# SYSCTRL_PADCONF_CORE register map
Vendor: Texas Instruments
Registers are 32-bit, access per field, reset 0x10F010F unless marked. A register's access mark holds for its fields unless they carry their own. Offsets are as the file gives them; [hi:lo] are bit positions; 'fields as' and 'values as' point back to an identical list.

## SYSCTRL_PADCONF_CORE (part 7 of 10)
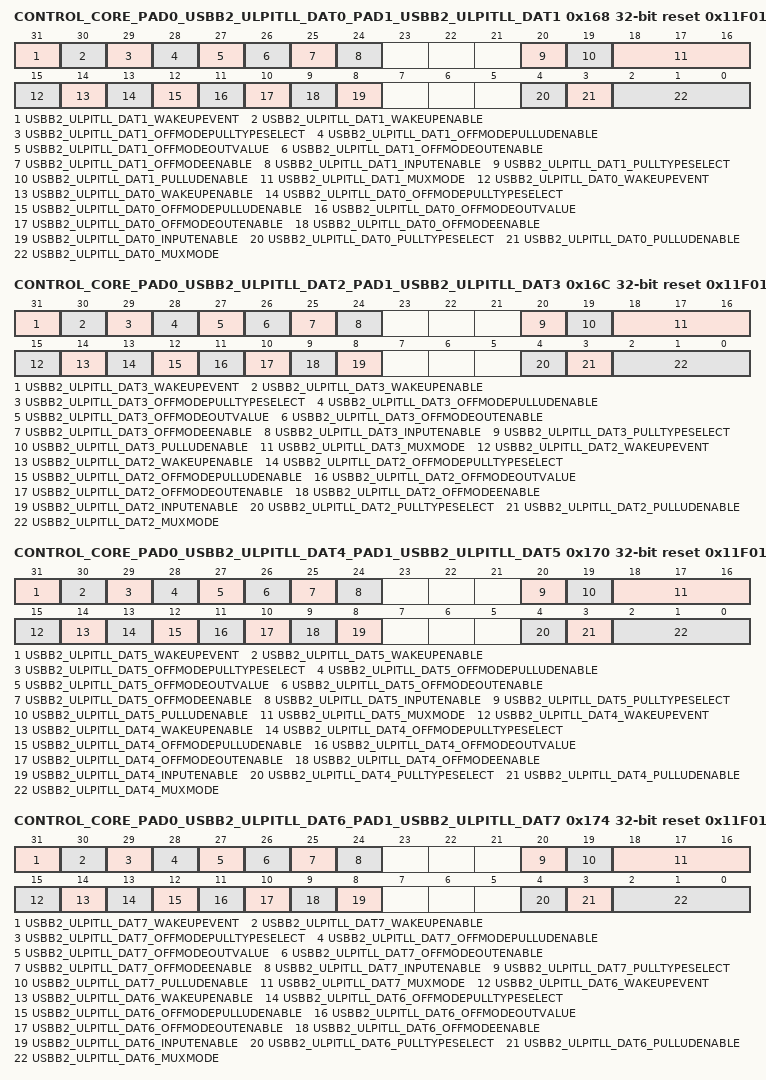
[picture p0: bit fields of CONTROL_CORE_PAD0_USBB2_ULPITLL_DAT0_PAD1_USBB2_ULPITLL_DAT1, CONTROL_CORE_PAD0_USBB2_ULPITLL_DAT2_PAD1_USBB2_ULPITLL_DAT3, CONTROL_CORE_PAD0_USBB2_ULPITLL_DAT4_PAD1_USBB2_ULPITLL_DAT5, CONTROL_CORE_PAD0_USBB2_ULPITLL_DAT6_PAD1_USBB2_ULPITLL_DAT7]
0x168 CONTROL_CORE_PAD0_USBB2_ULPITLL_DAT0_PAD1_USBB2_ULPITLL_DAT1 reset 0x11F011F — Register control for Pads usbb2_ulpitll_dat0 and usbb2_ulpitll_dat1 Access conditions. Read: unrestricted, Write: unrestricted
  [31] USBB2_ULPITLL_DAT1_WAKEUPEVENT ro — Pad_x wake-up event status latched in the IO
    0=USBB2_ULPITLL_DAT1_WAKEUPEVENT_0_r (No wake-up event occurred); 1=USBB2_ULPITLL_DAT1_WAKEUPEVENT_1_r (A wake-up event occurred)
  [30] USBB2_ULPITLL_DAT1_WAKEUPENABLE rw — Input pad wake-up enable (and OFF mode input enable value)
    0=wake-up detection is disabled; 1=wake-up detection is enabled
  [29] USBB2_ULPITLL_DAT1_OFFMODEPULLTYPESELECT rw — OffMode mode pullup/down selection for pad usbb2_ulpitll_dat1
    0=Offmode pulldown selected; 1=Offmode pullup selected
  [28] USBB2_ULPITLL_DAT1_OFFMODEPULLUDENABLE rw — OffMode mode pullup/down enable for pad usbb2_ulpitll_dat1
    0=Offmode pullup/down disabled; 1=Offmode pullup/down enabled
  [27] USBB2_ULPITLL_DAT1_OFFMODEOUTVALUE rw — OffMode mode output value for pad usbb2_ulpitll_dat1
    0=Set value at 0; 1=Set value at 1
  [26] USBB2_ULPITLL_DAT1_OFFMODEOUTENABLE rw — OffMode mode output enable value for pad usbb2_ulpitll_dat1. This is an active low signal
    0=Output enable; 1=Output disable
  [25] USBB2_ULPITLL_DAT1_OFFMODEENABLE rw — OffMode mode override control for pad usbb2_ulpitll_dat1
    0=I/O state keeps its previous state when OFF mode is active; 1=I/O state is forced to OFF mode value when OFF mode is active
  [24] USBB2_ULPITLL_DAT1_INPUTENABLE rw — Input enable value for pad usbb2_ulpitll_dat1
    0=Input buffer of I/O cell is disabled; 1=Input buffer of I/O cell is enabled
  [20] USBB2_ULPITLL_DAT1_PULLTYPESELECT rw — pullup/down selection for pad usbb2_ulpitll_dat1
    0=pulldown selected; 1=pullup selected
  [19] USBB2_ULPITLL_DAT1_PULLUDENABLE rw — pullup/down enable for pad usbb2_ulpitll_dat1
    0=pullup/down disabled; 1=pullup/down enabled
  [18:16] USBB2_ULPITLL_DAT1_MUXMODE rw — Functional multiplexing selection for pad usbb2_ulpitll_dat1
    0=Select usbb2_ulpitll_dat1; 1=Select usbb2_ulpiphy_dat1; 2=Select sdmmc4_dat3; 3=Select gpio_162; 4=Select hsi2_acdata; 5=Select dispc2_data19; 6=Select usbb2_mm_txdat; 7=Select safe_mode
  [15] USBB2_ULPITLL_DAT0_WAKEUPEVENT ro — Pad_x wake-up event status latched in the IO
    0=USBB2_ULPITLL_DAT0_WAKEUPEVENT_0_r (No wake-up event occurred); 1=USBB2_ULPITLL_DAT0_WAKEUPEVENT_1_r (A wake-up event occurred)
  [14] USBB2_ULPITLL_DAT0_WAKEUPENABLE rw — Input pad wake-up enable (and OFF mode input enable value)
    values as USBB2_ULPITLL_DAT1_WAKEUPENABLE
  [13] USBB2_ULPITLL_DAT0_OFFMODEPULLTYPESELECT rw — OffMode mode pullup/down selection for pad usbb2_ulpitll_dat0
    0=Offmode pulldown selected; 1=Offmode pullup selected
  [12] USBB2_ULPITLL_DAT0_OFFMODEPULLUDENABLE rw — OffMode mode pullup/down enable for pad usbb2_ulpitll_dat0
    values as USBB2_ULPITLL_DAT1_OFFMODEPULLUDENABLE
  [11] USBB2_ULPITLL_DAT0_OFFMODEOUTVALUE rw — OffMode mode output value for pad usbb2_ulpitll_dat0
    0=Set value at 0; 1=Set value at 1
  [10] USBB2_ULPITLL_DAT0_OFFMODEOUTENABLE rw — OffMode mode output enable value for pad usbb2_ulpitll_dat0. This is an active low signal
    0=Output enable; 1=Output disable
  [9] USBB2_ULPITLL_DAT0_OFFMODEENABLE rw — OffMode mode override control for pad usbb2_ulpitll_dat0
    values as USBB2_ULPITLL_DAT1_OFFMODEENABLE
  [8] USBB2_ULPITLL_DAT0_INPUTENABLE rw — Input enable value for pad usbb2_ulpitll_dat0
    values as USBB2_ULPITLL_DAT1_INPUTENABLE
  [4] USBB2_ULPITLL_DAT0_PULLTYPESELECT rw — pullup/down selection for pad usbb2_ulpitll_dat0
    0=pulldown selected; 1=pullup selected
  [3] USBB2_ULPITLL_DAT0_PULLUDENABLE rw — pullup/down enable for pad usbb2_ulpitll_dat0
    0=pullup/down disabled; 1=pullup/down enabled
  [2:0] USBB2_ULPITLL_DAT0_MUXMODE rw — Functional multiplexing selection for pad usbb2_ulpitll_dat0
    0=Select usbb2_ulpitll_dat0; 1=Select usbb2_ulpiphy_dat0; 2=Select sdmmc4_dat2; 3=Select gpio_161; 4=Select hsi2_acwake; 5=Select dispc2_data20; 6=Select usbb2_mm_txen; 7=Select safe_mode
0x16C CONTROL_CORE_PAD0_USBB2_ULPITLL_DAT2_PAD1_USBB2_ULPITLL_DAT3 reset 0x11F010F — Register control for Pads usbb2_ulpitll_dat2 and usbb2_ulpitll_dat3 Access conditions. Read: unrestricted, Write: unrestricted
  [31] USBB2_ULPITLL_DAT3_WAKEUPEVENT ro — Pad_x wake-up event status latched in the IO
    0=USBB2_ULPITLL_DAT3_WAKEUPEVENT_0_r (No wake-up event occurred); 1=USBB2_ULPITLL_DAT3_WAKEUPEVENT_1_r (A wake-up event occurred)
  [30] USBB2_ULPITLL_DAT3_WAKEUPENABLE rw — Input pad wake-up enable (and OFF mode input enable value)
    values as CONTROL_CORE_PAD0_USBB2_ULPITLL_DAT0_PAD1_USBB2_ULPITLL_DAT1.USBB2_ULPITLL_DAT1_WAKEUPENABLE
  [29] USBB2_ULPITLL_DAT3_OFFMODEPULLTYPESELECT rw — OffMode mode pullup/down selection for pad usbb2_ulpitll_dat3
    0=Offmode pulldown selected; 1=Offmode pullup selected
  [28] USBB2_ULPITLL_DAT3_OFFMODEPULLUDENABLE rw — OffMode mode pullup/down enable for pad usbb2_ulpitll_dat3
    values as CONTROL_CORE_PAD0_USBB2_ULPITLL_DAT0_PAD1_USBB2_ULPITLL_DAT1.USBB2_ULPITLL_DAT1_OFFMODEPULLUDENABLE
  [27] USBB2_ULPITLL_DAT3_OFFMODEOUTVALUE rw — OffMode mode output value for pad usbb2_ulpitll_dat3
    0=Set value at 0; 1=Set value at 1
  [26] USBB2_ULPITLL_DAT3_OFFMODEOUTENABLE rw — OffMode mode output enable value for pad usbb2_ulpitll_dat3. This is an active low signal
    0=Output enable; 1=Output disable
  [25] USBB2_ULPITLL_DAT3_OFFMODEENABLE rw — OffMode mode override control for pad usbb2_ulpitll_dat3
    values as CONTROL_CORE_PAD0_USBB2_ULPITLL_DAT0_PAD1_USBB2_ULPITLL_DAT1.USBB2_ULPITLL_DAT1_OFFMODEENABLE
  [24] USBB2_ULPITLL_DAT3_INPUTENABLE rw — Input enable value for pad usbb2_ulpitll_dat3
    values as CONTROL_CORE_PAD0_USBB2_ULPITLL_DAT0_PAD1_USBB2_ULPITLL_DAT1.USBB2_ULPITLL_DAT1_INPUTENABLE
  [20] USBB2_ULPITLL_DAT3_PULLTYPESELECT rw — pullup/down selection for pad usbb2_ulpitll_dat3
    0=pulldown selected; 1=pullup selected
  [19] USBB2_ULPITLL_DAT3_PULLUDENABLE rw — pullup/down enable for pad usbb2_ulpitll_dat3
    0=pullup/down disabled; 1=pullup/down enabled
  [18:16] USBB2_ULPITLL_DAT3_MUXMODE rw — Functional multiplexing selection for pad usbb2_ulpitll_dat3
    0=Select usbb2_ulpitll_dat3; 1=Select usbb2_ulpiphy_dat3; 2=Select sdmmc3_dat1; 3=Select gpio_164; 4=Select hsi2_caready; 5=Select dispc2_data15; 6=Select rfbi_data15; 7=Select safe_mode
  [15] USBB2_ULPITLL_DAT2_WAKEUPEVENT ro — Pad_x wake-up event status latched in the IO
    0=USBB2_ULPITLL_DAT2_WAKEUPEVENT_0_r (No wake-up event occurred); 1=USBB2_ULPITLL_DAT2_WAKEUPEVENT_1_r (A wake-up event occurred)
  [14] USBB2_ULPITLL_DAT2_WAKEUPENABLE rw — Input pad wake-up enable (and OFF mode input enable value)
    values as CONTROL_CORE_PAD0_USBB2_ULPITLL_DAT0_PAD1_USBB2_ULPITLL_DAT1.USBB2_ULPITLL_DAT1_WAKEUPENABLE
  [13] USBB2_ULPITLL_DAT2_OFFMODEPULLTYPESELECT rw — OffMode mode pullup/down selection for pad usbb2_ulpitll_dat2
    0=Offmode pulldown selected; 1=Offmode pullup selected
  [12] USBB2_ULPITLL_DAT2_OFFMODEPULLUDENABLE rw — OffMode mode pullup/down enable for pad usbb2_ulpitll_dat2
    values as CONTROL_CORE_PAD0_USBB2_ULPITLL_DAT0_PAD1_USBB2_ULPITLL_DAT1.USBB2_ULPITLL_DAT1_OFFMODEPULLUDENABLE
  [11] USBB2_ULPITLL_DAT2_OFFMODEOUTVALUE rw — OffMode mode output value for pad usbb2_ulpitll_dat2
    0=Set value at 0; 1=Set value at 1
  [10] USBB2_ULPITLL_DAT2_OFFMODEOUTENABLE rw — OffMode mode output enable value for pad usbb2_ulpitll_dat2. This is an active low signal
    0=Output enable; 1=Output disable
  [9] USBB2_ULPITLL_DAT2_OFFMODEENABLE rw — OffMode mode override control for pad usbb2_ulpitll_dat2
    values as CONTROL_CORE_PAD0_USBB2_ULPITLL_DAT0_PAD1_USBB2_ULPITLL_DAT1.USBB2_ULPITLL_DAT1_OFFMODEENABLE
  [8] USBB2_ULPITLL_DAT2_INPUTENABLE rw — Input enable value for pad usbb2_ulpitll_dat2
    values as CONTROL_CORE_PAD0_USBB2_ULPITLL_DAT0_PAD1_USBB2_ULPITLL_DAT1.USBB2_ULPITLL_DAT1_INPUTENABLE
  [4] USBB2_ULPITLL_DAT2_PULLTYPESELECT rw — pullup/down selection for pad usbb2_ulpitll_dat2
    0=pulldown selected; 1=pullup selected
  [3] USBB2_ULPITLL_DAT2_PULLUDENABLE rw — pullup/down enable for pad usbb2_ulpitll_dat2
    0=pullup/down disabled; 1=pullup/down enabled
  [2:0] USBB2_ULPITLL_DAT2_MUXMODE rw — Functional multiplexing selection for pad usbb2_ulpitll_dat2
    0=Select usbb2_ulpitll_dat2; 1=Select usbb2_ulpiphy_dat2; 2=Select sdmmc3_dat2; 3=Select gpio_163; 4=Select hsi2_acflag; 5=Select dispc2_data18; 6=Select usbb2_mm_txse0; 7=Select safe_mode
0x170 CONTROL_CORE_PAD0_USBB2_ULPITLL_DAT4_PAD1_USBB2_ULPITLL_DAT5 reset 0x11F011F — Register control for Pads usbb2_ulpitll_dat4 and usbb2_ulpitll_dat5 Access conditions. Read: unrestricted, Write: unrestricted
  [31] USBB2_ULPITLL_DAT5_WAKEUPEVENT ro — Pad_x wake-up event status latched in the IO
    0=USBB2_ULPITLL_DAT5_WAKEUPEVENT_0_r (No wake-up event occurred); 1=USBB2_ULPITLL_DAT5_WAKEUPEVENT_1_r (A wake-up event occurred)
  [30] USBB2_ULPITLL_DAT5_WAKEUPENABLE rw — Input pad wake-up enable (and OFF mode input enable value)
    values as CONTROL_CORE_PAD0_USBB2_ULPITLL_DAT0_PAD1_USBB2_ULPITLL_DAT1.USBB2_ULPITLL_DAT1_WAKEUPENABLE
  [29] USBB2_ULPITLL_DAT5_OFFMODEPULLTYPESELECT rw — OffMode mode pullup/down selection for pad usbb2_ulpitll_dat5
    0=Offmode pulldown selected; 1=Offmode pullup selected
  [28] USBB2_ULPITLL_DAT5_OFFMODEPULLUDENABLE rw — OffMode mode pullup/down enable for pad usbb2_ulpitll_dat5
    values as CONTROL_CORE_PAD0_USBB2_ULPITLL_DAT0_PAD1_USBB2_ULPITLL_DAT1.USBB2_ULPITLL_DAT1_OFFMODEPULLUDENABLE
  [27] USBB2_ULPITLL_DAT5_OFFMODEOUTVALUE rw — OffMode mode output value for pad usbb2_ulpitll_dat5
    0=Set value at 0; 1=Set value at 1
  [26] USBB2_ULPITLL_DAT5_OFFMODEOUTENABLE rw — OffMode mode output enable value for pad usbb2_ulpitll_dat5. This is an active low signal
    0=Output enable; 1=Output disable
  [25] USBB2_ULPITLL_DAT5_OFFMODEENABLE rw — OffMode mode override control for pad usbb2_ulpitll_dat5
    values as CONTROL_CORE_PAD0_USBB2_ULPITLL_DAT0_PAD1_USBB2_ULPITLL_DAT1.USBB2_ULPITLL_DAT1_OFFMODEENABLE
  [24] USBB2_ULPITLL_DAT5_INPUTENABLE rw — Input enable value for pad usbb2_ulpitll_dat5
    values as CONTROL_CORE_PAD0_USBB2_ULPITLL_DAT0_PAD1_USBB2_ULPITLL_DAT1.USBB2_ULPITLL_DAT1_INPUTENABLE
  [20] USBB2_ULPITLL_DAT5_PULLTYPESELECT rw — pullup/down selection for pad usbb2_ulpitll_dat5
    0=pulldown selected; 1=pullup selected
  [19] USBB2_ULPITLL_DAT5_PULLUDENABLE rw — pullup/down enable for pad usbb2_ulpitll_dat5
    0=pullup/down disabled; 1=pullup/down enabled
  [18:16] USBB2_ULPITLL_DAT5_MUXMODE rw — Functional multiplexing selection for pad usbb2_ulpitll_dat5
    0=Select usbb2_ulpitll_dat5; 1=Select usbb2_ulpiphy_dat5; 2=Select sdmmc3_dat3; 3=Select gpio_166; 4=Select mcspi3_cs0; 5=Select dispc2_data13; 6=Select rfbi_data13; 7=Select safe_mode
  [15] USBB2_ULPITLL_DAT4_WAKEUPEVENT ro — Pad_x wake-up event status latched in the IO
    0=USBB2_ULPITLL_DAT4_WAKEUPEVENT_0_r (No wake-up event occurred); 1=USBB2_ULPITLL_DAT4_WAKEUPEVENT_1_r (A wake-up event occurred)
  [14] USBB2_ULPITLL_DAT4_WAKEUPENABLE rw — Input pad wake-up enable (and OFF mode input enable value)
    values as CONTROL_CORE_PAD0_USBB2_ULPITLL_DAT0_PAD1_USBB2_ULPITLL_DAT1.USBB2_ULPITLL_DAT1_WAKEUPENABLE
  [13] USBB2_ULPITLL_DAT4_OFFMODEPULLTYPESELECT rw — OffMode mode pullup/down selection for pad usbb2_ulpitll_dat4
    0=Offmode pulldown selected; 1=Offmode pullup selected
  [12] USBB2_ULPITLL_DAT4_OFFMODEPULLUDENABLE rw — OffMode mode pullup/down enable for pad usbb2_ulpitll_dat4
    values as CONTROL_CORE_PAD0_USBB2_ULPITLL_DAT0_PAD1_USBB2_ULPITLL_DAT1.USBB2_ULPITLL_DAT1_OFFMODEPULLUDENABLE
  [11] USBB2_ULPITLL_DAT4_OFFMODEOUTVALUE rw — OffMode mode output value for pad usbb2_ulpitll_dat4
    0=Set value at 0; 1=Set value at 1
  [10] USBB2_ULPITLL_DAT4_OFFMODEOUTENABLE rw — OffMode mode output enable value for pad usbb2_ulpitll_dat4. This is an active low signal
    0=Output enable; 1=Output disable
  [9] USBB2_ULPITLL_DAT4_OFFMODEENABLE rw — OffMode mode override control for pad usbb2_ulpitll_dat4
    values as CONTROL_CORE_PAD0_USBB2_ULPITLL_DAT0_PAD1_USBB2_ULPITLL_DAT1.USBB2_ULPITLL_DAT1_OFFMODEENABLE
  [8] USBB2_ULPITLL_DAT4_INPUTENABLE rw — Input enable value for pad usbb2_ulpitll_dat4
    values as CONTROL_CORE_PAD0_USBB2_ULPITLL_DAT0_PAD1_USBB2_ULPITLL_DAT1.USBB2_ULPITLL_DAT1_INPUTENABLE
  [4] USBB2_ULPITLL_DAT4_PULLTYPESELECT rw — pullup/down selection for pad usbb2_ulpitll_dat4
    0=pulldown selected; 1=pullup selected
  [3] USBB2_ULPITLL_DAT4_PULLUDENABLE rw — pullup/down enable for pad usbb2_ulpitll_dat4
    0=pullup/down disabled; 1=pullup/down enabled
  [2:0] USBB2_ULPITLL_DAT4_MUXMODE rw — Functional multiplexing selection for pad usbb2_ulpitll_dat4
    0=Select usbb2_ulpitll_dat4; 1=Select usbb2_ulpiphy_dat4; 2=Select sdmmc3_dat0; 3=Select gpio_165; 4=Select mcspi3_somi; 5=Select dispc2_data14; 6=Select rfbi_data14; 7=Select safe_mode
0x174 CONTROL_CORE_PAD0_USBB2_ULPITLL_DAT6_PAD1_USBB2_ULPITLL_DAT7 reset 0x11F011F — Register control for Pads usbb2_ulpitll_dat6 and usbb2_ulpitll_dat7 Access conditions. Read: unrestricted, Write: unrestricted
  [31] USBB2_ULPITLL_DAT7_WAKEUPEVENT ro — Pad_x wake-up event status latched in the IO
    0=USBB2_ULPITLL_DAT7_WAKEUPEVENT_0_r (No wake-up event occurred); 1=USBB2_ULPITLL_DAT7_WAKEUPEVENT_1_r (A wake-up event occurred)
  [30] USBB2_ULPITLL_DAT7_WAKEUPENABLE rw — Input pad wake-up enable (and OFF mode input enable value)
    values as CONTROL_CORE_PAD0_USBB2_ULPITLL_DAT0_PAD1_USBB2_ULPITLL_DAT1.USBB2_ULPITLL_DAT1_WAKEUPENABLE
  [29] USBB2_ULPITLL_DAT7_OFFMODEPULLTYPESELECT rw — OffMode mode pullup/down selection for pad usbb2_ulpitll_dat7
    0=Offmode pulldown selected; 1=Offmode pullup selected
  [28] USBB2_ULPITLL_DAT7_OFFMODEPULLUDENABLE rw — OffMode mode pullup/down enable for pad usbb2_ulpitll_dat7
    values as CONTROL_CORE_PAD0_USBB2_ULPITLL_DAT0_PAD1_USBB2_ULPITLL_DAT1.USBB2_ULPITLL_DAT1_OFFMODEPULLUDENABLE
  [27] USBB2_ULPITLL_DAT7_OFFMODEOUTVALUE rw — OffMode mode output value for pad usbb2_ulpitll_dat7
    0=Set value at 0; 1=Set value at 1
  [26] USBB2_ULPITLL_DAT7_OFFMODEOUTENABLE rw — OffMode mode output enable value for pad usbb2_ulpitll_dat7. This is an active low signal
    0=Output enable; 1=Output disable
  [25] USBB2_ULPITLL_DAT7_OFFMODEENABLE rw — OffMode mode override control for pad usbb2_ulpitll_dat7
    values as CONTROL_CORE_PAD0_USBB2_ULPITLL_DAT0_PAD1_USBB2_ULPITLL_DAT1.USBB2_ULPITLL_DAT1_OFFMODEENABLE
  [24] USBB2_ULPITLL_DAT7_INPUTENABLE rw — Input enable value for pad usbb2_ulpitll_dat7
    values as CONTROL_CORE_PAD0_USBB2_ULPITLL_DAT0_PAD1_USBB2_ULPITLL_DAT1.USBB2_ULPITLL_DAT1_INPUTENABLE
  [20] USBB2_ULPITLL_DAT7_PULLTYPESELECT rw — pullup/down selection for pad usbb2_ulpitll_dat7
    0=pulldown selected; 1=pullup selected
  [19] USBB2_ULPITLL_DAT7_PULLUDENABLE rw — pullup/down enable for pad usbb2_ulpitll_dat7
    0=pullup/down disabled; 1=pullup/down enabled
  [18:16] USBB2_ULPITLL_DAT7_MUXMODE rw — Functional multiplexing selection for pad usbb2_ulpitll_dat7
    0=Select usbb2_ulpitll_dat7; 1=Select usbb2_ulpiphy_dat7; 2=Select sdmmc3_clk; 3=Select gpio_168; 4=Select mcspi3_clk; 5=Select dispc2_data11; 6=Select rfbi_data11; 7=Select safe_mode
  [15] USBB2_ULPITLL_DAT6_WAKEUPEVENT ro — Pad_x wake-up event status latched in the IO
    0=USBB2_ULPITLL_DAT6_WAKEUPEVENT_0_r (No wake-up event occurred); 1=USBB2_ULPITLL_DAT6_WAKEUPEVENT_1_r (A wake-up event occurred)
  [14] USBB2_ULPITLL_DAT6_WAKEUPENABLE rw — Input pad wake-up enable (and OFF mode input enable value)
    values as CONTROL_CORE_PAD0_USBB2_ULPITLL_DAT0_PAD1_USBB2_ULPITLL_DAT1.USBB2_ULPITLL_DAT1_WAKEUPENABLE
  [13] USBB2_ULPITLL_DAT6_OFFMODEPULLTYPESELECT rw — OffMode mode pullup/down selection for pad usbb2_ulpitll_dat6
    0=Offmode pulldown selected; 1=Offmode pullup selected
  [12] USBB2_ULPITLL_DAT6_OFFMODEPULLUDENABLE rw — OffMode mode pullup/down enable for pad usbb2_ulpitll_dat6
    values as CONTROL_CORE_PAD0_USBB2_ULPITLL_DAT0_PAD1_USBB2_ULPITLL_DAT1.USBB2_ULPITLL_DAT1_OFFMODEPULLUDENABLE
  [11] USBB2_ULPITLL_DAT6_OFFMODEOUTVALUE rw — OffMode mode output value for pad usbb2_ulpitll_dat6
    0=Set value at 0; 1=Set value at 1
  [10] USBB2_ULPITLL_DAT6_OFFMODEOUTENABLE rw — OffMode mode output enable value for pad usbb2_ulpitll_dat6. This is an active low signal
    0=Output enable; 1=Output disable
  [9] USBB2_ULPITLL_DAT6_OFFMODEENABLE rw — OffMode mode override control for pad usbb2_ulpitll_dat6
    values as CONTROL_CORE_PAD0_USBB2_ULPITLL_DAT0_PAD1_USBB2_ULPITLL_DAT1.USBB2_ULPITLL_DAT1_OFFMODEENABLE
  [8] USBB2_ULPITLL_DAT6_INPUTENABLE rw — Input enable value for pad usbb2_ulpitll_dat6
    values as CONTROL_CORE_PAD0_USBB2_ULPITLL_DAT0_PAD1_USBB2_ULPITLL_DAT1.USBB2_ULPITLL_DAT1_INPUTENABLE
  [4] USBB2_ULPITLL_DAT6_PULLTYPESELECT rw — pullup/down selection for pad usbb2_ulpitll_dat6
    0=pulldown selected; 1=pullup selected
  [3] USBB2_ULPITLL_DAT6_PULLUDENABLE rw — pullup/down enable for pad usbb2_ulpitll_dat6
    0=pullup/down disabled; 1=pullup/down enabled
  [2:0] USBB2_ULPITLL_DAT6_MUXMODE rw — Functional multiplexing selection for pad usbb2_ulpitll_dat6
    0=Select usbb2_ulpitll_dat6; 1=Select usbb2_ulpiphy_dat6; 2=Select sdmmc3_cmd; 3=Select gpio_167; 4=Select mcspi3_simo; 5=Select dispc2_data12; 6=Select rfbi_data12; 7=Select safe_mode
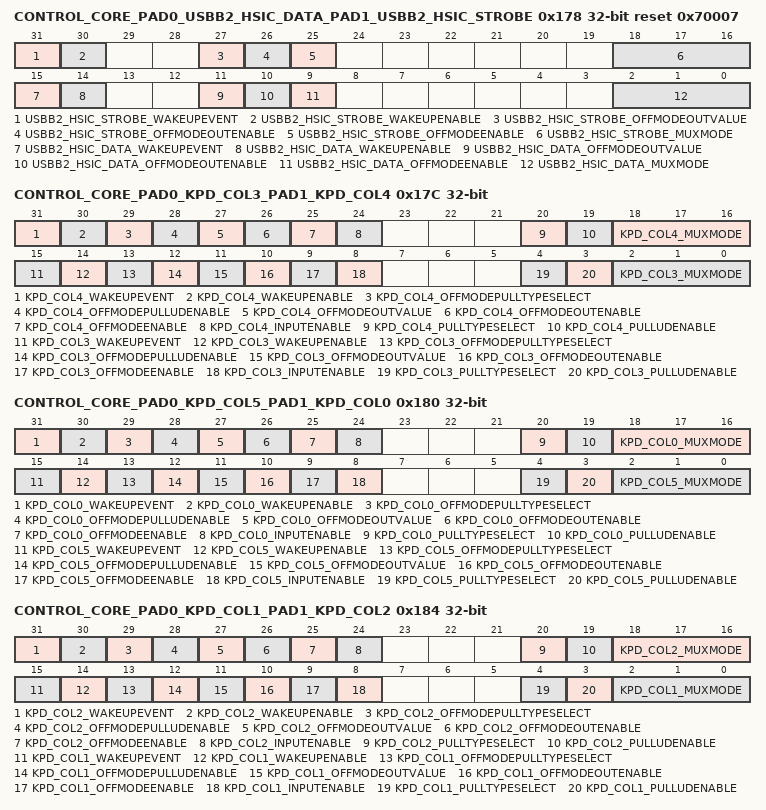
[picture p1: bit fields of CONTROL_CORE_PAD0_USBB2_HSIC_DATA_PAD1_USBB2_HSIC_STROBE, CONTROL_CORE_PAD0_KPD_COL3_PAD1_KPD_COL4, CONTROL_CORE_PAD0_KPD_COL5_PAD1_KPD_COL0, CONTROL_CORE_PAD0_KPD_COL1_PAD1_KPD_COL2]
0x178 CONTROL_CORE_PAD0_USBB2_HSIC_DATA_PAD1_USBB2_HSIC_STROBE reset 0x70007 — Register control for Pads usbb2_hsic_data and usbb2_hsic_strobe Access conditions. Read: unrestricted, Write: unrestricted
  [31] USBB2_HSIC_STROBE_WAKEUPEVENT ro — Pad_x wake-up event status latched in the IO
    0=USBB2_HSIC_STROBE_WAKEUPEVENT_0_r (No wake-up event occurred); 1=USBB2_HSIC_STROBE_WAKEUPEVENT_1_r (A wake-up event occurred)
  [30] USBB2_HSIC_STROBE_WAKEUPENABLE rw — Input pad wake-up enable (and OFF mode input enable value)
    values as CONTROL_CORE_PAD0_USBB2_ULPITLL_DAT0_PAD1_USBB2_ULPITLL_DAT1.USBB2_ULPITLL_DAT1_WAKEUPENABLE
  [27] USBB2_HSIC_STROBE_OFFMODEOUTVALUE rw — OffMode mode output value for pad usbb2_hsic_strobe
    0=Set value at 0; 1=Set value at 1
  [26] USBB2_HSIC_STROBE_OFFMODEOUTENABLE rw — OffMode mode output enable value for pad usbb2_hsic_strobe. This is an active low signal
    0=Output enable; 1=Output disable
  [25] USBB2_HSIC_STROBE_OFFMODEENABLE rw — OffMode mode override control for pad usbb2_hsic_strobe
    values as CONTROL_CORE_PAD0_USBB2_ULPITLL_DAT0_PAD1_USBB2_ULPITLL_DAT1.USBB2_ULPITLL_DAT1_OFFMODEENABLE
  [18:16] USBB2_HSIC_STROBE_MUXMODE rw — Functional multiplexing selection for pad usbb2_hsic_strobe
    0=Select usbb2_hsic_strobe; 3=Select gpio_170; 7=Select safe_mode
  [15] USBB2_HSIC_DATA_WAKEUPEVENT ro — Pad_x wake-up event status latched in the IO
    0=USBB2_HSIC_DATA_WAKEUPEVENT_0_r (No wake-up event occurred); 1=USBB2_HSIC_DATA_WAKEUPEVENT_1_r (A wake-up event occurred)
  [14] USBB2_HSIC_DATA_WAKEUPENABLE rw — Input pad wake-up enable (and OFF mode input enable value)
    values as CONTROL_CORE_PAD0_USBB2_ULPITLL_DAT0_PAD1_USBB2_ULPITLL_DAT1.USBB2_ULPITLL_DAT1_WAKEUPENABLE
  [11] USBB2_HSIC_DATA_OFFMODEOUTVALUE rw — OffMode mode output value for pad usbb2_hsic_data
    0=Set value at 0; 1=Set value at 1
  [10] USBB2_HSIC_DATA_OFFMODEOUTENABLE rw — OffMode mode output enable value for pad usbb2_hsic_data. This is an active low signal
    0=Output enable; 1=Output disable
  [9] USBB2_HSIC_DATA_OFFMODEENABLE rw — OffMode mode override control for pad usbb2_hsic_data
    values as CONTROL_CORE_PAD0_USBB2_ULPITLL_DAT0_PAD1_USBB2_ULPITLL_DAT1.USBB2_ULPITLL_DAT1_OFFMODEENABLE
  [2:0] USBB2_HSIC_DATA_MUXMODE rw — Functional multiplexing selection for pad usbb2_hsic_data
    0=Select usbb2_hsic_data; 3=Select gpio_169; 7=Select safe_mode
0x17C CONTROL_CORE_PAD0_KPD_COL3_PAD1_KPD_COL4 — Register control for Pads kpd_col3 and kpd_col4 Access conditions. Read: unrestricted, Write: unrestricted
  [31] KPD_COL4_WAKEUPEVENT ro — Pad_x wake-up event status latched in the IO
    0=KPD_COL4_WAKEUPEVENT_0_r (No wake-up event occurred); 1=KPD_COL4_WAKEUPEVENT_1_r (A wake-up event occurred)
  [30] KPD_COL4_WAKEUPENABLE rw — Input pad wake-up enable (and OFF mode input enable value)
    values as CONTROL_CORE_PAD0_USBB2_ULPITLL_DAT0_PAD1_USBB2_ULPITLL_DAT1.USBB2_ULPITLL_DAT1_WAKEUPENABLE
  [29] KPD_COL4_OFFMODEPULLTYPESELECT rw — OffMode mode pullup/down selection for pad kpd_col4
    0=Offmode pulldown selected; 1=Offmode pullup selected
  [28] KPD_COL4_OFFMODEPULLUDENABLE rw — OffMode mode pullup/down enable for pad kpd_col4
    values as CONTROL_CORE_PAD0_USBB2_ULPITLL_DAT0_PAD1_USBB2_ULPITLL_DAT1.USBB2_ULPITLL_DAT1_OFFMODEPULLUDENABLE
  [27] KPD_COL4_OFFMODEOUTVALUE rw — OffMode mode output value for pad kpd_col4
    0=Set value at 0; 1=Set value at 1
  [26] KPD_COL4_OFFMODEOUTENABLE rw — OffMode mode output enable value for pad kpd_col4. This is an active low signal
    0=Output enable; 1=Output disable
  [25] KPD_COL4_OFFMODEENABLE rw — OffMode mode override control for pad kpd_col4
    values as CONTROL_CORE_PAD0_USBB2_ULPITLL_DAT0_PAD1_USBB2_ULPITLL_DAT1.USBB2_ULPITLL_DAT1_OFFMODEENABLE
  [24] KPD_COL4_INPUTENABLE rw — Input enable value for pad kpd_col4
    values as CONTROL_CORE_PAD0_USBB2_ULPITLL_DAT0_PAD1_USBB2_ULPITLL_DAT1.USBB2_ULPITLL_DAT1_INPUTENABLE
  [20] KPD_COL4_PULLTYPESELECT rw — pullup/down selection for pad kpd_col4
    0=pulldown selected; 1=pullup selected
  [19] KPD_COL4_PULLUDENABLE rw — pullup/down enable for pad kpd_col4
    0=pullup/down disabled; 1=pullup/down enabled
  [18:16] KPD_COL4_MUXMODE rw — Functional multiplexing selection for pad kpd_col4
    0=Select kpd_col4; 1=Select kpd_col1; 3=Select gpio_172; 7=Select safe_mode
  [15] KPD_COL3_WAKEUPEVENT ro — Pad_x wake-up event status latched in the IO
    0=KPD_COL3_WAKEUPEVENT_0_r (No wake-up event occurred); 1=KPD_COL3_WAKEUPEVENT_1_r (A wake-up event occurred)
  [14] KPD_COL3_WAKEUPENABLE rw — Input pad wake-up enable (and OFF mode input enable value)
    values as CONTROL_CORE_PAD0_USBB2_ULPITLL_DAT0_PAD1_USBB2_ULPITLL_DAT1.USBB2_ULPITLL_DAT1_WAKEUPENABLE
  [13] KPD_COL3_OFFMODEPULLTYPESELECT rw — OffMode mode pullup/down selection for pad kpd_col3
    0=Offmode pulldown selected; 1=Offmode pullup selected
  [12] KPD_COL3_OFFMODEPULLUDENABLE rw — OffMode mode pullup/down enable for pad kpd_col3
    values as CONTROL_CORE_PAD0_USBB2_ULPITLL_DAT0_PAD1_USBB2_ULPITLL_DAT1.USBB2_ULPITLL_DAT1_OFFMODEPULLUDENABLE
  [11] KPD_COL3_OFFMODEOUTVALUE rw — OffMode mode output value for pad kpd_col3
    0=Set value at 0; 1=Set value at 1
  [10] KPD_COL3_OFFMODEOUTENABLE rw — OffMode mode output enable value for pad kpd_col3. This is an active low signal
    0=Output enable; 1=Output disable
  [9] KPD_COL3_OFFMODEENABLE rw — OffMode mode override control for pad kpd_col3
    values as CONTROL_CORE_PAD0_USBB2_ULPITLL_DAT0_PAD1_USBB2_ULPITLL_DAT1.USBB2_ULPITLL_DAT1_OFFMODEENABLE
  [8] KPD_COL3_INPUTENABLE rw — Input enable value for pad kpd_col3
    values as CONTROL_CORE_PAD0_USBB2_ULPITLL_DAT0_PAD1_USBB2_ULPITLL_DAT1.USBB2_ULPITLL_DAT1_INPUTENABLE
  [4] KPD_COL3_PULLTYPESELECT rw — pullup/down selection for pad kpd_col3
    0=pulldown selected; 1=pullup selected
  [3] KPD_COL3_PULLUDENABLE rw — pullup/down enable for pad kpd_col3
    0=pullup/down disabled; 1=pullup/down enabled
  [2:0] KPD_COL3_MUXMODE rw — Functional multiplexing selection for pad kpd_col3
    0=Select kpd_col3; 1=Select kpd_col0; 3=Select gpio_171; 7=Select safe_mode
0x180 CONTROL_CORE_PAD0_KPD_COL5_PAD1_KPD_COL0 — Register control for Pads kpd_col5 and kpd_col0 Access conditions. Read: unrestricted, Write: unrestricted
  [31] KPD_COL0_WAKEUPEVENT ro — Pad_x wake-up event status latched in the IO
    0=KPD_COL0_WAKEUPEVENT_0_r (No wake-up event occurred); 1=KPD_COL0_WAKEUPEVENT_1_r (A wake-up event occurred)
  [30] KPD_COL0_WAKEUPENABLE rw — Input pad wake-up enable (and OFF mode input enable value)
    values as CONTROL_CORE_PAD0_USBB2_ULPITLL_DAT0_PAD1_USBB2_ULPITLL_DAT1.USBB2_ULPITLL_DAT1_WAKEUPENABLE
  [29] KPD_COL0_OFFMODEPULLTYPESELECT rw — OffMode mode pullup/down selection for pad kpd_col0
    0=Offmode pulldown selected; 1=Offmode pullup selected
  [28] KPD_COL0_OFFMODEPULLUDENABLE rw — OffMode mode pullup/down enable for pad kpd_col0
    values as CONTROL_CORE_PAD0_USBB2_ULPITLL_DAT0_PAD1_USBB2_ULPITLL_DAT1.USBB2_ULPITLL_DAT1_OFFMODEPULLUDENABLE
  [27] KPD_COL0_OFFMODEOUTVALUE rw — OffMode mode output value for pad kpd_col0
    0=Set value at 0; 1=Set value at 1
  [26] KPD_COL0_OFFMODEOUTENABLE rw — OffMode mode output enable value for pad kpd_col0. This is an active low signal
    0=Output enable; 1=Output disable
  [25] KPD_COL0_OFFMODEENABLE rw — OffMode mode override control for pad kpd_col0
    values as CONTROL_CORE_PAD0_USBB2_ULPITLL_DAT0_PAD1_USBB2_ULPITLL_DAT1.USBB2_ULPITLL_DAT1_OFFMODEENABLE
  [24] KPD_COL0_INPUTENABLE rw — Input enable value for pad kpd_col0
    values as CONTROL_CORE_PAD0_USBB2_ULPITLL_DAT0_PAD1_USBB2_ULPITLL_DAT1.USBB2_ULPITLL_DAT1_INPUTENABLE
  [20] KPD_COL0_PULLTYPESELECT rw — pullup/down selection for pad kpd_col0
    0=pulldown selected; 1=pullup selected
  [19] KPD_COL0_PULLUDENABLE rw — pullup/down enable for pad kpd_col0
    0=pullup/down disabled; 1=pullup/down enabled
  [18:16] KPD_COL0_MUXMODE rw — Functional multiplexing selection for pad kpd_col0
    0=Select kpd_col0; 1=Select kpd_col3; 3=Select gpio_174; 7=Select safe_mode
  [15] KPD_COL5_WAKEUPEVENT ro — Pad_x wake-up event status latched in the IO
    0=KPD_COL5_WAKEUPEVENT_0_r (No wake-up event occurred); 1=KPD_COL5_WAKEUPEVENT_1_r (A wake-up event occurred)
  [14] KPD_COL5_WAKEUPENABLE rw — Input pad wake-up enable (and OFF mode input enable value)
    values as CONTROL_CORE_PAD0_USBB2_ULPITLL_DAT0_PAD1_USBB2_ULPITLL_DAT1.USBB2_ULPITLL_DAT1_WAKEUPENABLE
  [13] KPD_COL5_OFFMODEPULLTYPESELECT rw — OffMode mode pullup/down selection for pad kpd_col5
    0=Offmode pulldown selected; 1=Offmode pullup selected
  [12] KPD_COL5_OFFMODEPULLUDENABLE rw — OffMode mode pullup/down enable for pad kpd_col5
    values as CONTROL_CORE_PAD0_USBB2_ULPITLL_DAT0_PAD1_USBB2_ULPITLL_DAT1.USBB2_ULPITLL_DAT1_OFFMODEPULLUDENABLE
  [11] KPD_COL5_OFFMODEOUTVALUE rw — OffMode mode output value for pad kpd_col5
    0=Set value at 0; 1=Set value at 1
  [10] KPD_COL5_OFFMODEOUTENABLE rw — OffMode mode output enable value for pad kpd_col5. This is an active low signal
    0=Output enable; 1=Output disable
  [9] KPD_COL5_OFFMODEENABLE rw — OffMode mode override control for pad kpd_col5
    values as CONTROL_CORE_PAD0_USBB2_ULPITLL_DAT0_PAD1_USBB2_ULPITLL_DAT1.USBB2_ULPITLL_DAT1_OFFMODEENABLE
  [8] KPD_COL5_INPUTENABLE rw — Input enable value for pad kpd_col5
    values as CONTROL_CORE_PAD0_USBB2_ULPITLL_DAT0_PAD1_USBB2_ULPITLL_DAT1.USBB2_ULPITLL_DAT1_INPUTENABLE
  [4] KPD_COL5_PULLTYPESELECT rw — pullup/down selection for pad kpd_col5
    0=pulldown selected; 1=pullup selected
  [3] KPD_COL5_PULLUDENABLE rw — pullup/down enable for pad kpd_col5
    0=pullup/down disabled; 1=pullup/down enabled
  [2:0] KPD_COL5_MUXMODE rw — Functional multiplexing selection for pad kpd_col5
    0=Select kpd_col5; 1=Select kpd_col2; 3=Select gpio_173; 7=Select safe_mode
0x184 CONTROL_CORE_PAD0_KPD_COL1_PAD1_KPD_COL2 — Register control for Pads kpd_col1 and kpd_col2 Access conditions. Read: unrestricted, Write: unrestricted
  [31] KPD_COL2_WAKEUPEVENT ro — Pad_x wake-up event status latched in the IO
    0=KPD_COL2_WAKEUPEVENT_0_r (No wake-up event occurred); 1=KPD_COL2_WAKEUPEVENT_1_r (A wake-up event occurred)
  [30] KPD_COL2_WAKEUPENABLE rw — Input pad wake-up enable (and OFF mode input enable value)
    values as CONTROL_CORE_PAD0_USBB2_ULPITLL_DAT0_PAD1_USBB2_ULPITLL_DAT1.USBB2_ULPITLL_DAT1_WAKEUPENABLE
  [29] KPD_COL2_OFFMODEPULLTYPESELECT rw — OffMode mode pullup/down selection for pad kpd_col2
    0=Offmode pulldown selected; 1=Offmode pullup selected
  [28] KPD_COL2_OFFMODEPULLUDENABLE rw — OffMode mode pullup/down enable for pad kpd_col2
    values as CONTROL_CORE_PAD0_USBB2_ULPITLL_DAT0_PAD1_USBB2_ULPITLL_DAT1.USBB2_ULPITLL_DAT1_OFFMODEPULLUDENABLE
  [27] KPD_COL2_OFFMODEOUTVALUE rw — OffMode mode output value for pad kpd_col2
    0=Set value at 0; 1=Set value at 1
  [26] KPD_COL2_OFFMODEOUTENABLE rw — OffMode mode output enable value for pad kpd_col2. This is an active low signal
    0=Output enable; 1=Output disable
  [25] KPD_COL2_OFFMODEENABLE rw — OffMode mode override control for pad kpd_col2
    values as CONTROL_CORE_PAD0_USBB2_ULPITLL_DAT0_PAD1_USBB2_ULPITLL_DAT1.USBB2_ULPITLL_DAT1_OFFMODEENABLE
  [24] KPD_COL2_INPUTENABLE rw — Input enable value for pad kpd_col2
    values as CONTROL_CORE_PAD0_USBB2_ULPITLL_DAT0_PAD1_USBB2_ULPITLL_DAT1.USBB2_ULPITLL_DAT1_INPUTENABLE
  [20] KPD_COL2_PULLTYPESELECT rw — pullup/down selection for pad kpd_col2
    0=pulldown selected; 1=pullup selected
  [19] KPD_COL2_PULLUDENABLE rw — pullup/down enable for pad kpd_col2
    0=pullup/down disabled; 1=pullup/down enabled
  [18:16] KPD_COL2_MUXMODE rw — Functional multiplexing selection for pad kpd_col2
    0=Select kpd_col2; 1=Select kpd_col5; 3=Select gpio_1; 7=Select safe_mode
  [15] KPD_COL1_WAKEUPEVENT ro — Pad_x wake-up event status latched in the IO
    0=KPD_COL1_WAKEUPEVENT_0_r (No wake-up event occurred); 1=KPD_COL1_WAKEUPEVENT_1_r (A wake-up event occurred)
  [14] KPD_COL1_WAKEUPENABLE rw — Input pad wake-up enable (and OFF mode input enable value)
    values as CONTROL_CORE_PAD0_USBB2_ULPITLL_DAT0_PAD1_USBB2_ULPITLL_DAT1.USBB2_ULPITLL_DAT1_WAKEUPENABLE
  [13] KPD_COL1_OFFMODEPULLTYPESELECT rw — OffMode mode pullup/down selection for pad kpd_col1
    0=Offmode pulldown selected; 1=Offmode pullup selected
  [12] KPD_COL1_OFFMODEPULLUDENABLE rw — OffMode mode pullup/down enable for pad kpd_col1
    values as CONTROL_CORE_PAD0_USBB2_ULPITLL_DAT0_PAD1_USBB2_ULPITLL_DAT1.USBB2_ULPITLL_DAT1_OFFMODEPULLUDENABLE
  [11] KPD_COL1_OFFMODEOUTVALUE rw — OffMode mode output value for pad kpd_col1
    0=Set value at 0; 1=Set value at 1
  [10] KPD_COL1_OFFMODEOUTENABLE rw — OffMode mode output enable value for pad kpd_col1. This is an active low signal
    0=Output enable; 1=Output disable
  [9] KPD_COL1_OFFMODEENABLE rw — OffMode mode override control for pad kpd_col1
    values as CONTROL_CORE_PAD0_USBB2_ULPITLL_DAT0_PAD1_USBB2_ULPITLL_DAT1.USBB2_ULPITLL_DAT1_OFFMODEENABLE
  [8] KPD_COL1_INPUTENABLE rw — Input enable value for pad kpd_col1
    values as CONTROL_CORE_PAD0_USBB2_ULPITLL_DAT0_PAD1_USBB2_ULPITLL_DAT1.USBB2_ULPITLL_DAT1_INPUTENABLE
  [4] KPD_COL1_PULLTYPESELECT rw — pullup/down selection for pad kpd_col1
    0=pulldown selected; 1=pullup selected
  [3] KPD_COL1_PULLUDENABLE rw — pullup/down enable for pad kpd_col1
    0=pullup/down disabled; 1=pullup/down enabled
  [2:0] KPD_COL1_MUXMODE rw — Functional multiplexing selection for pad kpd_col1
    0=Select kpd_col1; 1=Select kpd_col4; 3=Select gpio_0; 7=Select safe_mode
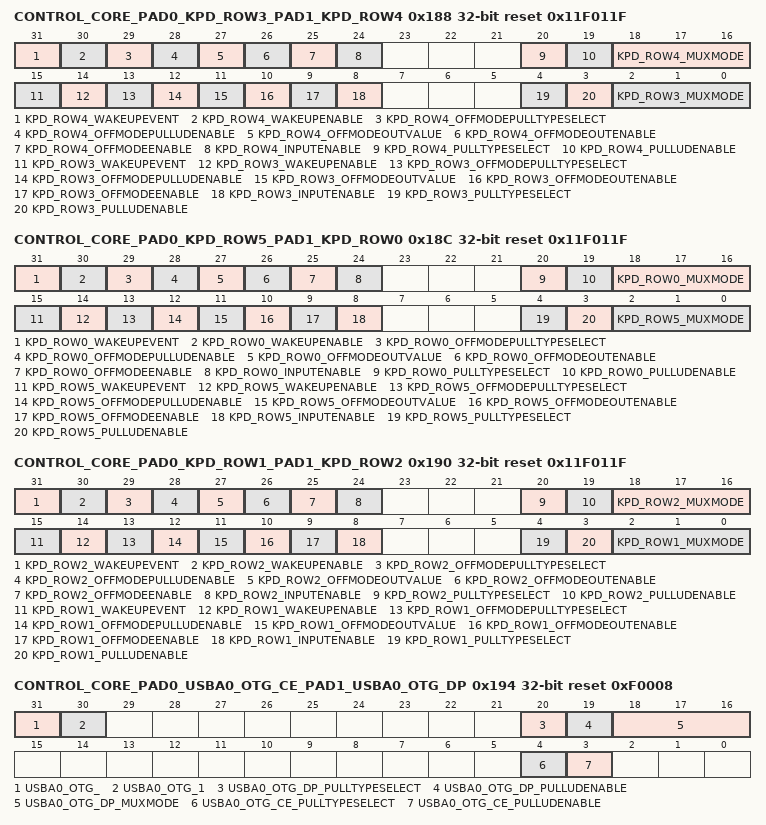
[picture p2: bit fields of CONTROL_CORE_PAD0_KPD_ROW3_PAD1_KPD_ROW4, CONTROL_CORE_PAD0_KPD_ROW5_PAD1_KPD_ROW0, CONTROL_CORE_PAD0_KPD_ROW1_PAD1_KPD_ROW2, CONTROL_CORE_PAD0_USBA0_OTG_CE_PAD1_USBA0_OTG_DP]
0x188 CONTROL_CORE_PAD0_KPD_ROW3_PAD1_KPD_ROW4 reset 0x11F011F — Register control for Pads kpd_row3 and kpd_row4 Access conditions. Read: unrestricted, Write: unrestricted
  [31] KPD_ROW4_WAKEUPEVENT ro — Pad_x wake-up event status latched in the IO
    0=KPD_ROW4_WAKEUPEVENT_0_r (No wake-up event occurred); 1=KPD_ROW4_WAKEUPEVENT_1_r (A wake-up event occurred)
  [30] KPD_ROW4_WAKEUPENABLE rw — Input pad wake-up enable (and OFF mode input enable value)
    values as CONTROL_CORE_PAD0_USBB2_ULPITLL_DAT0_PAD1_USBB2_ULPITLL_DAT1.USBB2_ULPITLL_DAT1_WAKEUPENABLE
  [29] KPD_ROW4_OFFMODEPULLTYPESELECT rw — OffMode mode pullup/down selection for pad kpd_row4
    0=Offmode pulldown selected; 1=Offmode pullup selected
  [28] KPD_ROW4_OFFMODEPULLUDENABLE rw — OffMode mode pullup/down enable for pad kpd_row4
    values as CONTROL_CORE_PAD0_USBB2_ULPITLL_DAT0_PAD1_USBB2_ULPITLL_DAT1.USBB2_ULPITLL_DAT1_OFFMODEPULLUDENABLE
  [27] KPD_ROW4_OFFMODEOUTVALUE rw — OffMode mode output value for pad kpd_row4
    0=Set value at 0; 1=Set value at 1
  [26] KPD_ROW4_OFFMODEOUTENABLE rw — OffMode mode output enable value for pad kpd_row4. This is an active low signal.
    0=Output enable; 1=Output disable
  [25] KPD_ROW4_OFFMODEENABLE rw — OffMode mode override control for pad kpd_row4
    0=I/O state keeps its previous state when off mode is active; 1=I/O state is forced to off mode value when offmode is active
  [24] KPD_ROW4_INPUTENABLE rw — Input enable value for pad kpd_row4
    values as CONTROL_CORE_PAD0_USBB2_ULPITLL_DAT0_PAD1_USBB2_ULPITLL_DAT1.USBB2_ULPITLL_DAT1_INPUTENABLE
  [20] KPD_ROW4_PULLTYPESELECT rw — pullup/down selection for pad kpd_row4
    0=pulldown selected; 1=pullup selected
  [19] KPD_ROW4_PULLUDENABLE rw — pullup/down enable for pad kpd_row4
    0=pullup/down disabled; 1=pullup/down enabled
  [18:16] KPD_ROW4_MUXMODE rw — Functional multiplexing selection for pad kpd_row4
    0=Select kpd_row4; 1=Select kpd_row1; 3=Select gpio_176; 7=Select safe_mode
  [15] KPD_ROW3_WAKEUPEVENT ro — Pad_x wake-up event status latched in the IO
    0=KPD_ROW3_WAKEUPEVENT_0_r (No wake-up event occurred); 1=KPD_ROW3_WAKEUPEVENT_1_r (A wake-up event occurred)
  [14] KPD_ROW3_WAKEUPENABLE rw — Input pad wake-up enable (and OFF mode input enable value)
    values as CONTROL_CORE_PAD0_USBB2_ULPITLL_DAT0_PAD1_USBB2_ULPITLL_DAT1.USBB2_ULPITLL_DAT1_WAKEUPENABLE
  [13] KPD_ROW3_OFFMODEPULLTYPESELECT rw — OffMode mode pullup/down selection for pad kpd_row3
    0=Offmode pulldown selected; 1=Offmode pullup selected
  [12] KPD_ROW3_OFFMODEPULLUDENABLE rw — OffMode mode pullup/down enable for pad kpd_row3
    values as CONTROL_CORE_PAD0_USBB2_ULPITLL_DAT0_PAD1_USBB2_ULPITLL_DAT1.USBB2_ULPITLL_DAT1_OFFMODEPULLUDENABLE
  [11] KPD_ROW3_OFFMODEOUTVALUE rw — OffMode mode output value for pad kpd_row3
    0=Set value at 0; 1=Set value at 1
  [10] KPD_ROW3_OFFMODEOUTENABLE rw — OffMode mode output enable value for pad kpd_row3. This is an active low signal.
    0=Output enable; 1=Output disable
  [9] KPD_ROW3_OFFMODEENABLE rw — OffMode mode override control for pad kpd_row3
    0=I/O state keeps its previous state when off mode is active; 1=I/O state is forced to off mode value when off mode is active
  [8] KPD_ROW3_INPUTENABLE rw — Input enable value for pad kpd_row3
    values as CONTROL_CORE_PAD0_USBB2_ULPITLL_DAT0_PAD1_USBB2_ULPITLL_DAT1.USBB2_ULPITLL_DAT1_INPUTENABLE
  [4] KPD_ROW3_PULLTYPESELECT rw — pullup/down selection for pad kpd_row3
    0=pulldown selected; 1=pullup selected
  [3] KPD_ROW3_PULLUDENABLE rw — pullup/down enable for pad kpd_row3
    0=pullup/down disabled; 1=pullup/down enabled
  [2:0] KPD_ROW3_MUXMODE rw — Functional multiplexing selection for pad kpd_row3
    0=Select kpd_row3; 1=Select kpd_row0; 3=Select gpio_175; 7=Select safe_mode
0x18C CONTROL_CORE_PAD0_KPD_ROW5_PAD1_KPD_ROW0 reset 0x11F011F — Register control for Pads kpd_row5 and kpd_row0 Access conditions. Read: unrestricted, Write: unrestricted
  [31] KPD_ROW0_WAKEUPEVENT ro — Pad_x wake-up event status latched in the IO
    0=KPD_ROW0_WAKEUPEVENT_0_r (No wake-up event occurred); 1=KPD_ROW0_WAKEUPEVENT_1_r (A wake-up event occurred)
  [30] KPD_ROW0_WAKEUPENABLE rw — Input pad wake-up enable (and OFF mode input enable value)
    values as CONTROL_CORE_PAD0_USBB2_ULPITLL_DAT0_PAD1_USBB2_ULPITLL_DAT1.USBB2_ULPITLL_DAT1_WAKEUPENABLE
  [29] KPD_ROW0_OFFMODEPULLTYPESELECT rw — OffMode mode pullup/down selection for pad kpd_row0
    0=Offmode pulldown selected; 1=Offmode pullup selected
  [28] KPD_ROW0_OFFMODEPULLUDENABLE rw — OffMode mode pullup/down enable for pad kpd_row0
    values as CONTROL_CORE_PAD0_USBB2_ULPITLL_DAT0_PAD1_USBB2_ULPITLL_DAT1.USBB2_ULPITLL_DAT1_OFFMODEPULLUDENABLE
  [27] KPD_ROW0_OFFMODEOUTVALUE rw — OffMode mode output value for pad kpd_row0
    0=Set value at 0; 1=Set value at 1
  [26] KPD_ROW0_OFFMODEOUTENABLE rw — OffMode mode output enable value for pad kpd_row0. This is an active low signal.
    0=Output enable; 1=Output disable
  [25] KPD_ROW0_OFFMODEENABLE rw — OffMode mode override control for pad kpd_row0
    values as CONTROL_CORE_PAD0_KPD_ROW3_PAD1_KPD_ROW4.KPD_ROW3_OFFMODEENABLE
  [24] KPD_ROW0_INPUTENABLE rw — Input enable value for pad kpd_row0
    values as CONTROL_CORE_PAD0_USBB2_ULPITLL_DAT0_PAD1_USBB2_ULPITLL_DAT1.USBB2_ULPITLL_DAT1_INPUTENABLE
  [20] KPD_ROW0_PULLTYPESELECT rw — pullup/down selection for pad kpd_row0
    0=pulldown selected; 1=pullup selected
  [19] KPD_ROW0_PULLUDENABLE rw — pullup/down enable for pad kpd_row0
    0=pullup/down disabled; 1=pullup/down enabled
  [18:16] KPD_ROW0_MUXMODE rw — Functional multiplexing selection for pad kpd_row0
    0=Select kpd_row0; 1=Select kpd_row3; 3=Select gpio_178; 7=Select safe_mode
  [15] KPD_ROW5_WAKEUPEVENT ro — Pad_x wake-up event status latched in the IO
    0=KPD_ROW5_WAKEUPEVENT_0_r (No wake-up event occurred); 1=KPD_ROW5_WAKEUPEVENT_1_r (A wake-up event occurred)
  [14] KPD_ROW5_WAKEUPENABLE rw — Input pad wake-up enable (and OFF mode input enable value)
    values as CONTROL_CORE_PAD0_USBB2_ULPITLL_DAT0_PAD1_USBB2_ULPITLL_DAT1.USBB2_ULPITLL_DAT1_WAKEUPENABLE
  [13] KPD_ROW5_OFFMODEPULLTYPESELECT rw — OffMode mode pullup/down selection for pad kpd_row5
    0=Offmode pulldown selected; 1=Offmode pullup selected
  [12] KPD_ROW5_OFFMODEPULLUDENABLE rw — OffMode mode pullup/down enable for pad kpd_row5
    values as CONTROL_CORE_PAD0_USBB2_ULPITLL_DAT0_PAD1_USBB2_ULPITLL_DAT1.USBB2_ULPITLL_DAT1_OFFMODEPULLUDENABLE
  [11] KPD_ROW5_OFFMODEOUTVALUE rw — OffMode mode output value for pad kpd_row5
    0=Set value at 0; 1=Set value at 1
  [10] KPD_ROW5_OFFMODEOUTENABLE rw — OffMode mode output enable value for pad kpd_row5. This is an active low signal.
    0=Output enable; 1=Output disable
  [9] KPD_ROW5_OFFMODEENABLE rw — OffMode mode override control for pad kpd_row5
    values as CONTROL_CORE_PAD0_KPD_ROW3_PAD1_KPD_ROW4.KPD_ROW3_OFFMODEENABLE
  [8] KPD_ROW5_INPUTENABLE rw — Input enable value for pad kpd_row5
    values as CONTROL_CORE_PAD0_USBB2_ULPITLL_DAT0_PAD1_USBB2_ULPITLL_DAT1.USBB2_ULPITLL_DAT1_INPUTENABLE
  [4] KPD_ROW5_PULLTYPESELECT rw — pullup/down selection for pad kpd_row5
    0=pulldown selected; 1=pullup selected
  [3] KPD_ROW5_PULLUDENABLE rw — pullup/down enable for pad kpd_row5
    0=pullup/down disabled; 1=pullup/down enabled
  [2:0] KPD_ROW5_MUXMODE rw — Functional multiplexing selection for pad kpd_row5
    0=Select kpd_row5; 1=Select kpd_row2; 3=Select gpio_177; 7=Select safe_mode
0x190 CONTROL_CORE_PAD0_KPD_ROW1_PAD1_KPD_ROW2 reset 0x11F011F — Register control for Pads kpd_row1 and kpd_row2 Access conditions. Read: unrestricted, Write: unrestricted
  [31] KPD_ROW2_WAKEUPEVENT ro — Pad_x wake-up event status latched in the IO
    0=KPD_ROW2_WAKEUPEVENT_0_r (No wake-up event occurred); 1=KPD_ROW2_WAKEUPEVENT_1_r (A wake-up event occurred)
  [30] KPD_ROW2_WAKEUPENABLE rw — Input pad wake-up enable (and OFF mode input enable value)
    values as CONTROL_CORE_PAD0_USBB2_ULPITLL_DAT0_PAD1_USBB2_ULPITLL_DAT1.USBB2_ULPITLL_DAT1_WAKEUPENABLE
  [29] KPD_ROW2_OFFMODEPULLTYPESELECT rw — OffMode mode pullup/down selection for pad kpd_row2
    0=Offmode pulldown selected; 1=Offmode pullup selected
  [28] KPD_ROW2_OFFMODEPULLUDENABLE rw — OffMode mode pullup/down enable for pad kpd_row2
    values as CONTROL_CORE_PAD0_USBB2_ULPITLL_DAT0_PAD1_USBB2_ULPITLL_DAT1.USBB2_ULPITLL_DAT1_OFFMODEPULLUDENABLE
  [27] KPD_ROW2_OFFMODEOUTVALUE rw — OffMode mode output value for pad kpd_row2
    0=Set value at 0; 1=Set value at 1
  [26] KPD_ROW2_OFFMODEOUTENABLE rw — OffMode mode output enable value for pad kpd_row2. This is an active low signal.
    0=Output enable; 1=Output disable
  [25] KPD_ROW2_OFFMODEENABLE rw — OffMode mode override control for pad kpd_row2
    values as CONTROL_CORE_PAD0_KPD_ROW3_PAD1_KPD_ROW4.KPD_ROW3_OFFMODEENABLE
  [24] KPD_ROW2_INPUTENABLE rw — Input enable value for pad kpd_row2
    values as CONTROL_CORE_PAD0_USBB2_ULPITLL_DAT0_PAD1_USBB2_ULPITLL_DAT1.USBB2_ULPITLL_DAT1_INPUTENABLE
  [20] KPD_ROW2_PULLTYPESELECT rw — pullup/down selection for pad kpd_row2
    0=pulldown selected; 1=pullup selected
  [19] KPD_ROW2_PULLUDENABLE rw — pullup/down enable for pad kpd_row2
    0=pullup/down disabled; 1=pullup/down enabled
  [18:16] KPD_ROW2_MUXMODE rw — Functional multiplexing selection for pad kpd_row2
    0=Select kpd_row2; 1=Select kpd_row5; 3=Select gpio_3; 7=Select safe_mode
  [15] KPD_ROW1_WAKEUPEVENT ro — Pad_x wake-up event status latched in the IO
    0=KPD_ROW1_WAKEUPEVENT_0_r (No wake-up event occurred); 1=KPD_ROW1_WAKEUPEVENT_1_r (A wake-up event occurred)
  [14] KPD_ROW1_WAKEUPENABLE rw — Input pad wake-up enable (and OFF mode input enable value)
    values as CONTROL_CORE_PAD0_USBB2_ULPITLL_DAT0_PAD1_USBB2_ULPITLL_DAT1.USBB2_ULPITLL_DAT1_WAKEUPENABLE
  [13] KPD_ROW1_OFFMODEPULLTYPESELECT rw — OffMode mode pullup/down selection for pad kpd_row1
    0=Offmode pulldown selected; 1=Offmode pullup selected
  [12] KPD_ROW1_OFFMODEPULLUDENABLE rw — OffMode mode pullup/down enable for pad kpd_row1
    values as CONTROL_CORE_PAD0_USBB2_ULPITLL_DAT0_PAD1_USBB2_ULPITLL_DAT1.USBB2_ULPITLL_DAT1_OFFMODEPULLUDENABLE
  [11] KPD_ROW1_OFFMODEOUTVALUE rw — OffMode mode output value for pad kpd_row1
    0=Set value at 0; 1=Set value at 1
  [10] KPD_ROW1_OFFMODEOUTENABLE rw — OffMode mode output enable value for pad kpd_row1. This is an active low signal
    0=Output enable; 1=Output disable
  [9] KPD_ROW1_OFFMODEENABLE rw — OffMode mode override control for pad kpd_row1
    values as CONTROL_CORE_PAD0_KPD_ROW3_PAD1_KPD_ROW4.KPD_ROW3_OFFMODEENABLE
  [8] KPD_ROW1_INPUTENABLE rw — Input enable value for pad kpd_row1
    values as CONTROL_CORE_PAD0_USBB2_ULPITLL_DAT0_PAD1_USBB2_ULPITLL_DAT1.USBB2_ULPITLL_DAT1_INPUTENABLE
  [4] KPD_ROW1_PULLTYPESELECT rw — pullup/down selection for pad kpd_row1
    0=pulldown selected; 1=pullup selected
  [3] KPD_ROW1_PULLUDENABLE rw — pullup/down enable for pad kpd_row1
    0=pullup/down disabled; 1=pullup/down enabled
  [2:0] KPD_ROW1_MUXMODE rw — Functional multiplexing selection for pad kpd_row1
    0=Select kpd_row1; 1=Select kpd_row4; 3=Select gpio_2; 7=Select safe_mode
0x194 CONTROL_CORE_PAD0_USBA0_OTG_CE_PAD1_USBA0_OTG_DP reset 0xF0008 — Register control for Pads usba0_otg_ce and usba0_otg_dp Access conditions. Read: unrestricted, Write: unrestricted
  [31] USBA0_OTG_ ro — Pad_x wake-up event status latched in the IO
    1=USBA0_OTG__1_r (A wake-up event occurred); 0=USBA0_OTG__0_r (No wake-up event occurred)
  [30] USBA0_OTG_1 rw — Input pad wake-up enable (and OFF mode input enable value)
    0=USBA0_OTG__0 (Wake-up detection on low level); 1=USBA0_OTG__1 (Wake-up detection on high level)
  [20] USBA0_OTG_DP_PULLTYPESELECT rw — Pullup/down selection for pad usba0_otg_dp
    0=Pulldown selected; 1=Pullup selected
  [19] USBA0_OTG_DP_PULLUDENABLE rw — Pullup/down enable for pad usba0_otg_dp
    0=Pullup/down disabled; 1=Pullup/down enabled
  [18:16] USBA0_OTG_DP_MUXMODE rw — Functional multiplexing selection for pad usba0_otg_dp
    0=Select usba0_otg_dp; 1=Select uart3_rx_irrx; 2=Select uart2_rx; 7=Select safe_mode
  [4] USBA0_OTG_CE_PULLTYPESELECT rw — Pullup/down selection for pad usba0_otg_ce
    0=Pulldown selected; 1=Pullup selected
  [3] USBA0_OTG_CE_PULLUDENABLE rw — Pullup/down enable for pad usba0_otg_ce
    0=Pullup/down disabled; 1=Pullup/down enabled
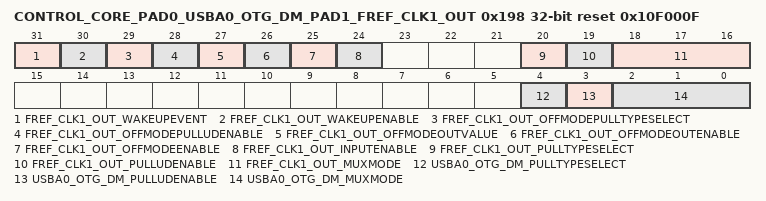
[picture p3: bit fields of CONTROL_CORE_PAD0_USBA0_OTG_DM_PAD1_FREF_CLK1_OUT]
0x198 CONTROL_CORE_PAD0_USBA0_OTG_DM_PAD1_FREF_CLK1_OUT reset 0x10F000F — Register control for Pads usba0_otg_dm and fref_clk1_out Access conditions. Read: unrestricted, Write: unrestricted
  [31] FREF_CLK1_OUT_WAKEUPEVENT ro — Pad_x wake-up event status latched in the IO
    0=FREF_CLK1_OUT_WAKEUPEVENT_0_r (No wake-up event occurred); 1=FREF_CLK1_OUT_WAKEUPEVENT_1_r (A wake-up event occurred)
  [30] FREF_CLK1_OUT_WAKEUPENABLE rw — Input pad wake-up enable (and OFF mode input enable value)
    values as CONTROL_CORE_PAD0_USBB2_ULPITLL_DAT0_PAD1_USBB2_ULPITLL_DAT1.USBB2_ULPITLL_DAT1_WAKEUPENABLE
  [29] FREF_CLK1_OUT_OFFMODEPULLTYPESELECT rw — OffMode mode pullup/down selection for pad fref_clk1_out
    0=Offmode pulldown selected; 1=Offmode pullup selected
  [28] FREF_CLK1_OUT_OFFMODEPULLUDENABLE rw — OffMode mode pullup/down enable for pad fref_clk1_out
    values as CONTROL_CORE_PAD0_USBB2_ULPITLL_DAT0_PAD1_USBB2_ULPITLL_DAT1.USBB2_ULPITLL_DAT1_OFFMODEPULLUDENABLE
  [27] FREF_CLK1_OUT_OFFMODEOUTVALUE rw — OffMode mode output value for pad fref_clk1_out
    0=Set value at 0; 1=Set value at 1
  [26] FREF_CLK1_OUT_OFFMODEOUTENABLE rw — OffMode mode output enable value for pad fref_clk1_out. This is an active low signal
    0=Output enable; 1=Output disable
  [25] FREF_CLK1_OUT_OFFMODEENABLE rw — OffMode mode override control for pad fref_clk1_out
    values as CONTROL_CORE_PAD0_USBB2_ULPITLL_DAT0_PAD1_USBB2_ULPITLL_DAT1.USBB2_ULPITLL_DAT1_OFFMODEENABLE
  [24] FREF_CLK1_OUT_INPUTENABLE rw — Input enable value for pad fref_clk1_out
    values as CONTROL_CORE_PAD0_USBB2_ULPITLL_DAT0_PAD1_USBB2_ULPITLL_DAT1.USBB2_ULPITLL_DAT1_INPUTENABLE
  [20] FREF_CLK1_OUT_PULLTYPESELECT rw — Pullup/down selection for pad fref_clk1_out
    0=Pulldown selected; 1=Pullup selected
  [19] FREF_CLK1_OUT_PULLUDENABLE rw — Pullup/down enable for pad fref_clk1_out
    0=Pullup/down disabled; 1=Pullup/down enabled
  [18:16] FREF_CLK1_OUT_MUXMODE rw — Functional multiplexing selection for pad fref_clk1_out
    0=Select fref_clk1_out; 3=Select gpio_181; 7=Select safe_mode
  [4] USBA0_OTG_DM_PULLTYPESELECT rw — Pullup/down selection for pad usba0_otg_dm
    0=Pulldown selected; 1=Pullup selected
  [3] USBA0_OTG_DM_PULLUDENABLE rw — Pullup/down enable for pad usba0_otg_dm
    0=Pullup/down disabled; 1=Pullup/down enabled
  [2:0] USBA0_OTG_DM_MUXMODE rw — Functional multiplexing selection for pad usba0_otg_dm
    0=Select usba0_otg_dm; 1=Select uart3_tx_irtx; 2=Select uart2_tx; 7=Select safe_mode
